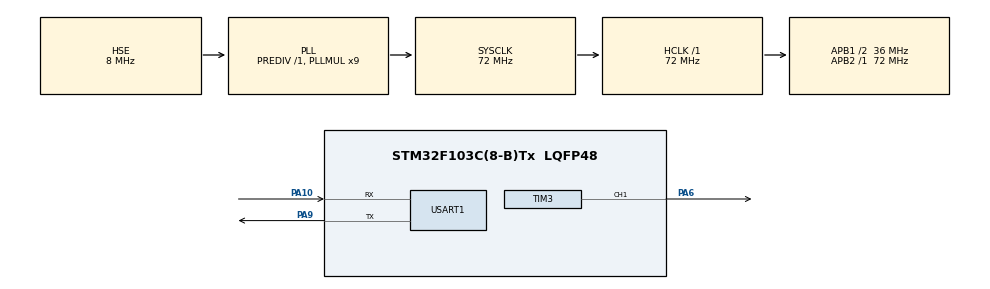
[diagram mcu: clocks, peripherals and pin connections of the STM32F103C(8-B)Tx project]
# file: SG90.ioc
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Mcu.Family=STM32F1
Mcu.Name=STM32F103C(8-B)Tx
Mcu.Package=LQFP48
NVIC.PriorityGroup=NVIC_PRIORITYGROUP_4
NVIC.USART1_IRQn=true\:0\:0\:false\:false\:true\:true\:true\:true
PA10.Mode=Asynchronous
PA10.Signal=USART1_RX
PA13.Mode=Serial_Wire
PA13.Signal=SYS_JTMS-SWDIO
PA14.Mode=Serial_Wire
PA14.Signal=SYS_JTCK-SWCLK
PA6.Signal=S_TIM3_CH1
PA9.Mode=Asynchronous
PA9.Signal=USART1_TX
PD0-OSC_IN.Mode=HSE-External-Oscillator
PD0-OSC_IN.Signal=RCC_OSC_IN
PD1-OSC_OUT.Mode=HSE-External-Oscillator
PD1-OSC_OUT.Signal=RCC_OSC_OUT
ProjectManager.HeapSize=0x200
ProjectManager.StackSize=0x400
ProjectManager.TargetToolchain=CMake
RCC.AHBFreq_Value=72000000
RCC.APB1CLKDivider=RCC_HCLK_DIV2
RCC.APB1Freq_Value=36000000
RCC.APB1TimFreq_Value=72000000
RCC.APB2Freq_Value=72000000
RCC.APB2TimFreq_Value=72000000
RCC.HCLKFreq_Value=72000000
RCC.PLLMUL=RCC_PLL_MUL9
RCC.PLLSourceVirtual=RCC_PLLSOURCE_HSE
RCC.SYSCLKFreq_VALUE=72000000
RCC.SYSCLKSource=RCC_SYSCLKSOURCE_PLLCLK
RCC.USBFreq_Value=72000000
SH.S_TIM3_CH1.0=TIM3_CH1,PWM Generation1 CH1
TIM3.AutoReloadPreload=TIM_AUTORELOAD_PRELOAD_ENABLE
TIM3.Channel-PWM\ Generation1\ CH1=TIM_CHANNEL_1
TIM3.Period=2000-1
TIM3.Prescaler=720-1
TIM3.Pulse-PWM\ Generation1\ CH1=150
USART1.VirtualMode=VM_ASYNC
VP_TIM3_VS_ClockSourceINT.Mode=Internal
board=custom

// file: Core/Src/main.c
/* USER CODE BEGIN Header */
/**
  ******************************************************************************
  * @file           : main.c
  * @brief          : Main program body
  ******************************************************************************
  * @attention
  *
  * Copyright (c) 2026 STMicroelectronics.
  * All rights reserved.
  *
  * This software is licensed under terms that can be found in the LICENSE file
  * in the root directory of this software component.
  * If no LICENSE file comes with this software, it is provided AS-IS.
  *
  ******************************************************************************
  */
/* USER CODE END Header */
#include "main.h"

TIM_HandleTypeDef htim3;

UART_HandleTypeDef huart1;

/* USER CODE BEGIN PV */
volatile uint16_t servo_angle = 90;
uint8_t rx_byte;
uint32_t rx_angle = 0;
uint8_t rx_has_digit = 0;

float vofa_data[2];
uint8_t vofa_tail[4] = {0x00, 0x00, 0x80, 0x7F};

/* USER CODE END PV */

void SystemClock_Config(void);
static void MX_GPIO_Init(void);
static void MX_TIM3_Init(void);
static void MX_USART1_UART_Init(void);

int main(void)
{

  /* MCU Configuration--------------------------------------------------------*/

  /* Reset of all peripherals, Initializes the Flash interface and the Systick. */
  HAL_Init();

  /* Configure the system clock */
  SystemClock_Config();

  /* Initialize all configured peripherals */
  MX_GPIO_Init();
  MX_TIM3_Init();
  MX_USART1_UART_Init();
  /* USER CODE BEGIN 2 */
  HAL_TIM_PWM_Start(&htim3, TIM_CHANNEL_1);
  HAL_UART_Receive_IT(&huart1, &rx_byte, 1);

  /* USER CODE END 2 */

  /* Infinite loop */
  while (1)
  {

    /* USER CODE BEGIN 3 */
    vofa_data[0] = (float)servo_angle;
    vofa_data[1] = (float)__HAL_TIM_GET_COMPARE(&htim3, TIM_CHANNEL_1) * 100.0f / 2000.0f;

    HAL_UART_Transmit(&huart1, (uint8_t *)vofa_data, sizeof(vofa_data), 100);
    HAL_UART_Transmit(&huart1, vofa_tail, sizeof(vofa_tail), 100);

    HAL_Delay(50);
  }
  /* USER CODE END 3 */
}

void SystemClock_Config(void)
{
  RCC_OscInitTypeDef RCC_OscInitStruct = {0};
  RCC_ClkInitTypeDef RCC_ClkInitStruct = {0};

  /** Initializes the RCC Oscillators according to the specified parameters
  * in the RCC_OscInitTypeDef structure.
  */
  RCC_OscInitStruct.OscillatorType = RCC_OSCILLATORTYPE_HSE;
  RCC_OscInitStruct.HSEState = RCC_HSE_ON;
  RCC_OscInitStruct.HSEPredivValue = RCC_HSE_PREDIV_DIV1;
  RCC_OscInitStruct.HSIState = RCC_HSI_ON;
  RCC_OscInitStruct.PLL.PLLState = RCC_PLL_ON;
  RCC_OscInitStruct.PLL.PLLSource = RCC_PLLSOURCE_HSE;
  RCC_OscInitStruct.PLL.PLLMUL = RCC_PLL_MUL9;
  if (HAL_RCC_OscConfig(&RCC_OscInitStruct) != HAL_OK)
  {
    Error_Handler();
  }

  /** Initializes the CPU, AHB and APB buses clocks
  */
  RCC_ClkInitStruct.ClockType = RCC_CLOCKTYPE_HCLK|RCC_CLOCKTYPE_SYSCLK
                              |RCC_CLOCKTYPE_PCLK1|RCC_CLOCKTYPE_PCLK2;
  RCC_ClkInitStruct.SYSCLKSource = RCC_SYSCLKSOURCE_PLLCLK;
  RCC_ClkInitStruct.AHBCLKDivider = RCC_SYSCLK_DIV1;
  RCC_ClkInitStruct.APB1CLKDivider = RCC_HCLK_DIV2;
  RCC_ClkInitStruct.APB2CLKDivider = RCC_HCLK_DIV1;

  if (HAL_RCC_ClockConfig(&RCC_ClkInitStruct, FLASH_LATENCY_2) != HAL_OK)
  {
    Error_Handler();
  }
}

static void MX_TIM3_Init(void)
{

  TIM_ClockConfigTypeDef sClockSourceConfig = {0};
  TIM_MasterConfigTypeDef sMasterConfig = {0};
  TIM_OC_InitTypeDef sConfigOC = {0};

  htim3.Instance = TIM3;
  htim3.Init.Prescaler = 720-1;
  htim3.Init.CounterMode = TIM_COUNTERMODE_UP;
  htim3.Init.Period = 2000-1;
  htim3.Init.ClockDivision = TIM_CLOCKDIVISION_DIV1;
  htim3.Init.AutoReloadPreload = TIM_AUTORELOAD_PRELOAD_ENABLE;
  if (HAL_TIM_Base_Init(&htim3) != HAL_OK)
  {
    Error_Handler();
  }
  sClockSourceConfig.ClockSource = TIM_CLOCKSOURCE_INTERNAL;
  if (HAL_TIM_ConfigClockSource(&htim3, &sClockSourceConfig) != HAL_OK)
  {
    Error_Handler();
  }
  if (HAL_TIM_PWM_Init(&htim3) != HAL_OK)
  {
    Error_Handler();
  }
  sMasterConfig.MasterOutputTrigger = TIM_TRGO_RESET;
  sMasterConfig.MasterSlaveMode = TIM_MASTERSLAVEMODE_DISABLE;
  if (HAL_TIMEx_MasterConfigSynchronization(&htim3, &sMasterConfig) != HAL_OK)
  {
    Error_Handler();
  }
  sConfigOC.OCMode = TIM_OCMODE_PWM1;
  sConfigOC.Pulse = 150;
  sConfigOC.OCPolarity = TIM_OCPOLARITY_HIGH;
  sConfigOC.OCFastMode = TIM_OCFAST_DISABLE;
  if (HAL_TIM_PWM_ConfigChannel(&htim3, &sConfigOC, TIM_CHANNEL_1) != HAL_OK)
  {
    Error_Handler();
  }
  HAL_TIM_MspPostInit(&htim3);

}

static void MX_USART1_UART_Init(void)
{

  huart1.Instance = USART1;
  huart1.Init.BaudRate = 115200;
  huart1.Init.WordLength = UART_WORDLENGTH_8B;
  huart1.Init.StopBits = UART_STOPBITS_1;
  huart1.Init.Parity = UART_PARITY_NONE;
  huart1.Init.Mode = UART_MODE_TX_RX;
  huart1.Init.HwFlowCtl = UART_HWCONTROL_NONE;
  huart1.Init.OverSampling = UART_OVERSAMPLING_16;
  if (HAL_UART_Init(&huart1) != HAL_OK)
  {
    Error_Handler();
  }

}

static void MX_GPIO_Init(void)
{

  /* GPIO Ports Clock Enable */
  __HAL_RCC_GPIOD_CLK_ENABLE();
  __HAL_RCC_GPIOA_CLK_ENABLE();

}

/* USER CODE BEGIN 4 */
void HAL_UART_RxCpltCallback(UART_HandleTypeDef *huart)
{
  if (huart->Instance == USART1)
  {
    if (rx_byte >= '0' && rx_byte <= '9')
    {
      if (rx_angle < 1000)
      {
        rx_angle = rx_angle * 10 + rx_byte - '0';
      }
      rx_has_digit = 1;
    }
    else if ((rx_byte == '\r' || rx_byte == '\n') && rx_has_digit)
    {
      if (rx_angle > 180)
      {
        rx_angle = 180;
      }

      servo_angle = (uint16_t)rx_angle;
      __HAL_TIM_SET_COMPARE(&htim3, TIM_CHANNEL_1, 50 + rx_angle * 200 / 180);

      rx_angle = 0;
      rx_has_digit = 0;
    }
    else
    {
      rx_angle = 0;
      rx_has_digit = 0;
    }

    HAL_UART_Receive_IT(&huart1, &rx_byte, 1);
  }
}
/* USER CODE END 4 */

void Error_Handler(void)
{
  __disable_irq();
  while (1)
  {
  }
}
